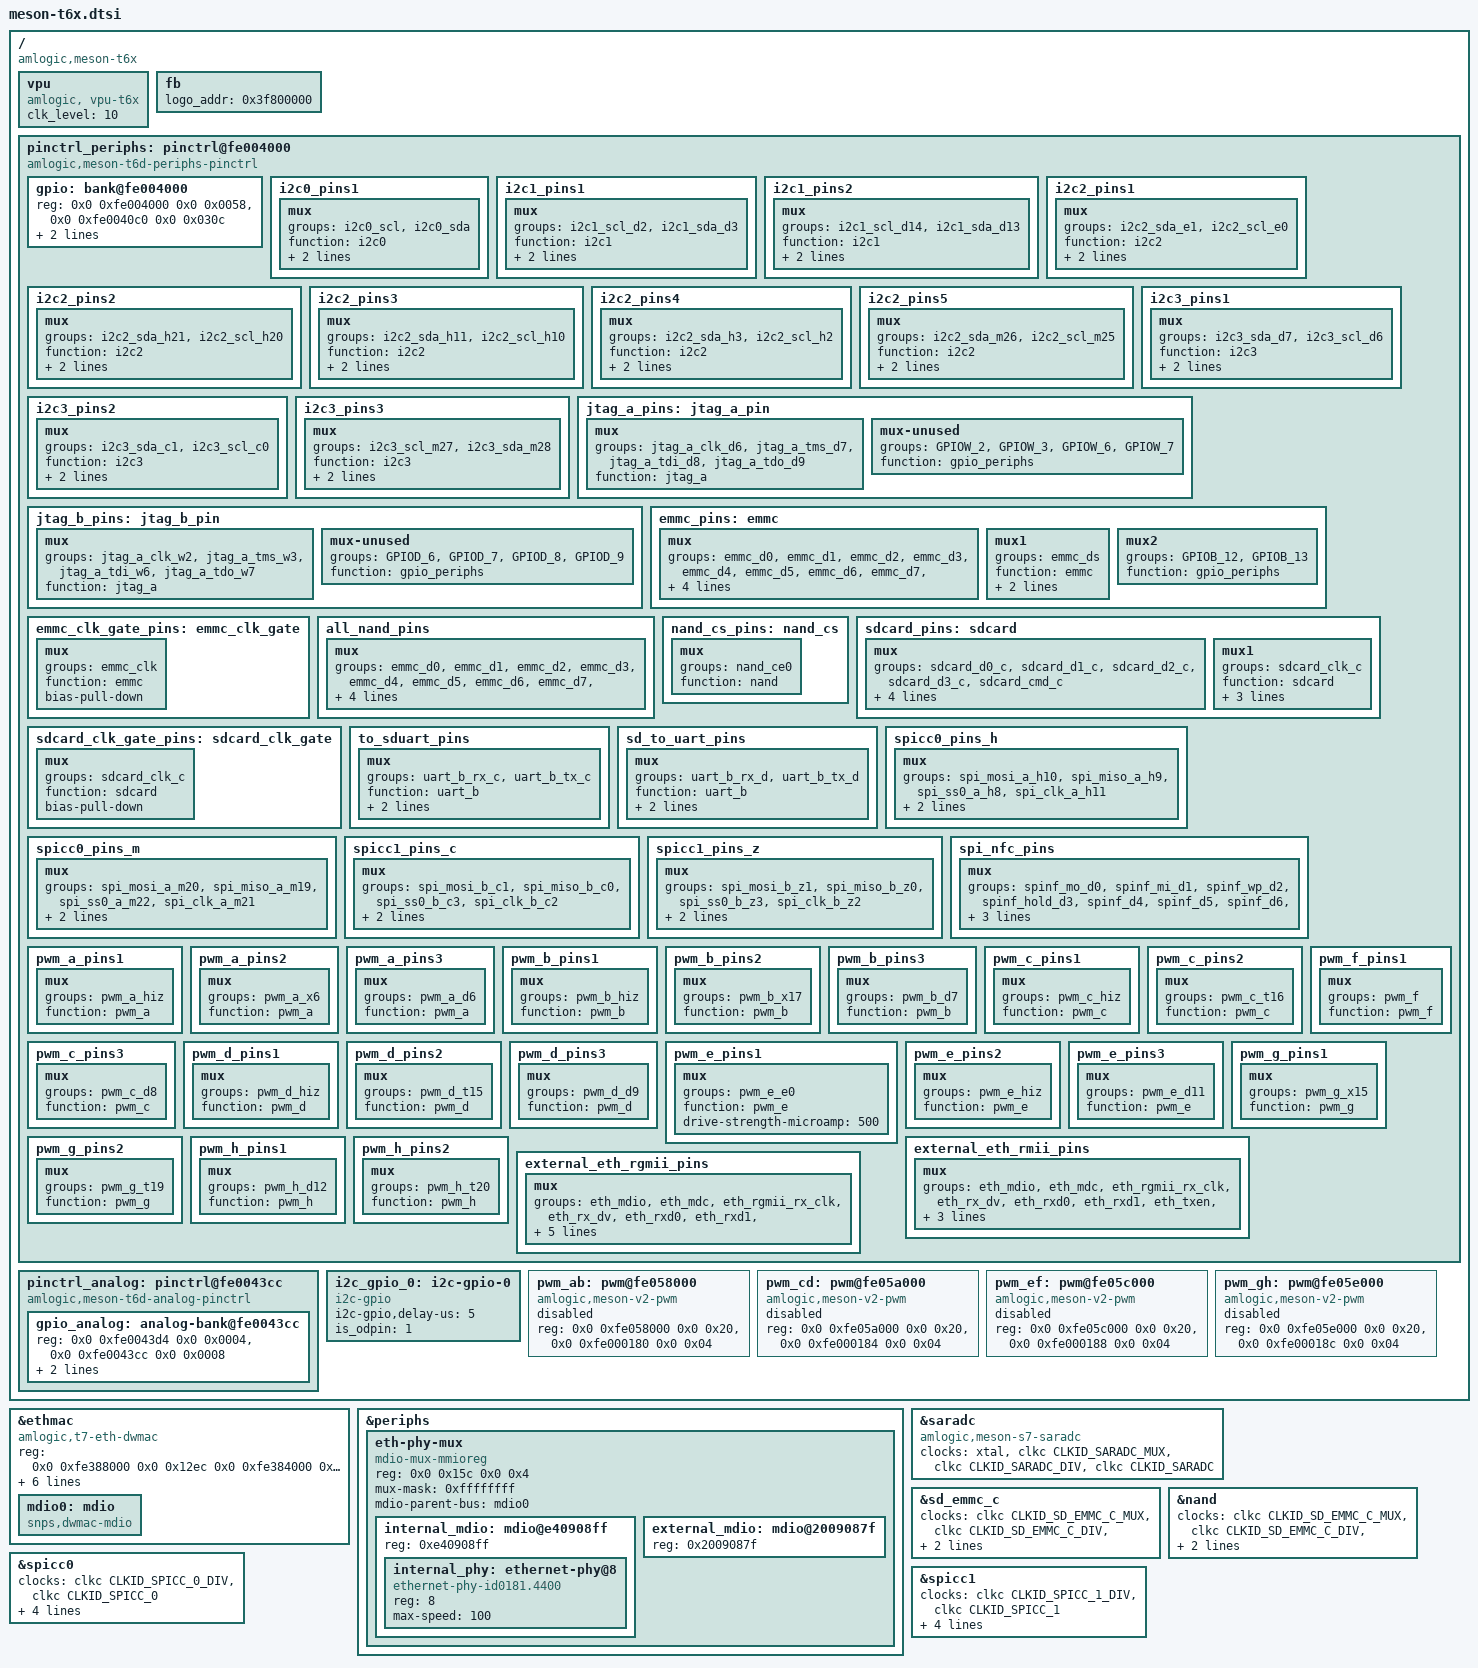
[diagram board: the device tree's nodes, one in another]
// SPDX-License-Identifier: (GPL-2.0+ OR MIT)
/*
 * Copyright (c) 2019 Amlogic, Inc. All rights reserved.
 */

#include "amlogic/meson-t6x-series.dtsi"
#include <dt-bindings/amlogic/gpio/meson-t6x-gpio.h>
#include <dt-bindings/reset/amlogic,meson-gxbb-reset.h>
#include <dt-bindings/amlogic/pwm/pwm.h>
#include <dt-bindings/amlogic/pwm/meson.h>

/ {
	compatible = "amlogic,meson-t6x";

	vpu: vpu {
		compatible = "amlogic, vpu-t6x";
		status = "okay";
		/*clocks = <&clkc CLKID_VAPB_MUX>,
		 *	<&clkc CLKID_VPU_INTR>,
		 *	<&clkc CLKID_VPU_P0_COMP>,
		 *	<&clkc CLKID_VPU_P1_COMP>,
		 *	<&clkc CLKID_VPU_MUX>;
		 *clock-names = "vapb_clk",
		 *	"vpu_intr_gate",
		 *	"vpu_clk0",
		 *	"vpu_clk1",
		 *	"vpu_clk";
		 */
		clk_level = <10>;
		/* 0: 100.0M    1: 166.7M    2: 200.0M    3: 250.0M */
		/* 4: 333.3M    5: 400.0M    6: 500.0M    7: 666.7M */
		/* 8: 800.0M    9: 696.0M(invalid)  10: 840.0M   11: 808.0M   */
	};

	fb {
		status = "okay";
		logo_addr = "0x3f800000";
	};

	pinctrl_periphs: pinctrl@fe004000 {
		compatible = "amlogic,meson-t6d-periphs-pinctrl";
		#address-cells = <2>;
		#size-cells = <2>;
		ranges;

		gpio: bank@fe004000 {
			reg = <0x0 0xfe004000 0x0 0x0058>,
			      <0x0 0xfe0040c0 0x0 0x030c>;
			reg-names = "mux", "gpio";
			gpio-controller;
			#gpio-cells = <2>;
			gpio-ranges = <&pinctrl_periphs 0 0 129>;
		};
	};

	pinctrl_analog: pinctrl@fe0043cc {
		compatible = "amlogic,meson-t6d-analog-pinctrl";
		#address-cells = <2>;
		#size-cells = <2>;
		ranges;

		gpio_analog: analog-bank@fe0043cc {
			reg = <0x0 0xfe0043d4 0x0 0x0004>,
			      <0x0 0xfe0043cc 0x0 0x0008>;
			reg-names = "mux", "gpio";
			gpio-controller;
			#gpio-cells = <2>;
			gpio-ranges = <&pinctrl_analog 0 0 2>;
		};
	};

	i2c_gpio_0: i2c-gpio-0 {
		#address-cells = <1>;
		#size-cells = <0>;

		compatible = "i2c-gpio";
		status = "okay";
		//gpios = <&gpio GPIOH_0 GPIO_ACTIVE_HIGH>, /* SDA */
		//	<&gpio GPIOH_1 GPIO_ACTIVE_HIGH>; /* CLK */

		i2c-gpio,delay-us = <5>;
		is_odpin = <1>;
	};

	pwm_ab: pwm@fe058000 {
		compatible = "amlogic,meson-v2-pwm";
		reg = <0x0 0xfe058000  0x0 0x20>,
			<0x0 0xfe000180  0x0 0x04>;
		#pwm-cells = <3>;
		status = "disabled";
	};

	pwm_cd: pwm@fe05a000 {
		compatible = "amlogic,meson-v2-pwm";
		reg = <0x0 0xfe05a000  0x0 0x20>,
			<0x0 0xfe000184  0x0 0x04>;
		#pwm-cells = <3>;
		status = "disabled";
	};

	pwm_ef: pwm@fe05c000 {
		compatible = "amlogic,meson-v2-pwm";
		reg = <0x0 0xfe05c000  0x0 0x20>,
			<0x0 0xfe000188  0x0 0x04>;
		#pwm-cells = <3>;
		status = "disabled";
	};

	pwm_gh: pwm@fe05e000 {
		compatible = "amlogic,meson-v2-pwm";
		reg = <0x0 0xfe05e000  0x0 0x20>,
			<0x0 0xfe00018c  0x0 0x04>;
			#pwm-cells = <3>;
		status = "disabled";
	};

};

&ethmac {
	compatible = "amlogic,t7-eth-dwmac";
	reg = <0x0 0xfe388000 0x0 0x12ec
		0x0 0xfe384000 0x0 0x8
		0x0 0xfe380000 0x0 0xa0>;
	reg-names = "eth_base", "eth_top", "eth_cfg";
	phy_cntl1 = <0x41054147>;
	internal_phy = <1>;
	mc_val = <0x4be04>;
	pll_val = <0x608200a0 0xea002000 0x00000150>;
	analog_val = <0x20200000 0x0000c000 0x00000023>;
	chip_num = <3>;
//	soc_num = <5>;
	/* 5: S1A, S7 */
	//tx_amp_src = <0xfe005b30>;
//	clocks = <&clkc CLKID_ETH_CORE>,
//		 <&clkc CLKID_FCLK_DIV2>,
//		 <&clkc CLKID_MPLL2>;
//	clock-names = "stmmaceth", "clkin0", "clkin1";

	mdio0: mdio {
		#address-cells = <1>;
		#size-cells = <0>;
		compatible = "snps,dwmac-mdio";
	};
};

&periphs {

	eth-phy-mux {
		compatible = "mdio-mux-mmioreg", "mdio-mux";
		#address-cells = <1>;
		#size-cells = <0>;
		reg = <0x0 0x15c 0x0 0x4>;
		mux-mask = <0xffffffff>;
		mdio-parent-bus = <&mdio0>;

		internal_mdio: mdio@e40908ff {
			reg = <0xe40908ff>;
			#address-cells = <1>;
			#size-cells = <0>;

			internal_phy: ethernet-phy@8 {
				compatible = "ethernet-phy-id0181.4400", "ethernet-phy-ieee802.3-c22";
				reg = <8>;
				max-speed = <100>;
			};
		};

		external_mdio: mdio@2009087f {
			reg = <0x2009087f>;
			#address-cells = <1>;
			#size-cells = <0>;
		};
	};
};

&saradc {
	compatible = "amlogic,meson-s7-saradc", "amlogic,meson-saradc";
	clocks = <&xtal>,
		 <&clkc CLKID_SARADC_MUX>,
		 <&clkc CLKID_SARADC_DIV>,
		 <&clkc CLKID_SARADC>;
	clock-names = "xtal", "adc_mux", "adc_div", "adc_gate";
};

&sd_emmc_c {
	 clocks = <&clkc CLKID_SD_EMMC_C_MUX>,
			<&clkc CLKID_SD_EMMC_C_DIV>,
			<&clkc CLKID_SD_EMMC_C>,
			<&clkc CLKID_GP0_PLL>,
			//<&clkc CLKID_FCLK_DIV2>,
			<&clkc CLKID_XTAL>;
			clock-names = "mux", "div", "gate", "clkin", "xtal";
};

&nand {
	clocks = <&clkc CLKID_SD_EMMC_C_MUX>,
			<&clkc CLKID_SD_EMMC_C_DIV>,
			<&clkc CLKID_SD_EMMC_C>,
			<&clkc CLKID_FCLK_DIV2>,
			<&clkc CLKID_XTAL>;
	clock-names = "mux", "div", "gate", "fdiv2", "xtal";
};

&spicc0 {
	clocks = <&clkc CLKID_SPICC_0_DIV>, <&clkc CLKID_SPICC_0>;
	clock-names = "spi_clk", "sys_clk";
	assigned-clocks = <&clkc CLKID_SPICC_0_MUX>, <&clkc CLKID_SPICC_0_DIV>;
	assigned-clock-parents = <&clkc CLKID_FCLK_DIV2>;
	assigned-clock-rates = <0>, <500000000>;
};

&spicc1 {
	clocks = <&clkc CLKID_SPICC_1_DIV>, <&clkc CLKID_SPICC_1>;
	clock-names = "spi_clk", "sys_clk";
	assigned-clocks = <&clkc CLKID_SPICC_1_MUX>, <&clkc CLKID_SPICC_1_DIV>;
	assigned-clock-parents = <&clkc CLKID_FCLK_DIV2>;
	assigned-clock-rates = <0>, <500000000>;
};

&pinctrl_periphs {
	i2c0_pins1:i2c0_pins1 {
		mux {
			groups = "i2c0_scl",
				"i2c0_sda";
			function = "i2c0";
			drive-strength = <3>;
			bias-disable;
		};
	};

	i2c1_pins1:i2c1_pins1 {
		mux {
			groups = "i2c1_scl_d2",
				"i2c1_sda_d3";
			function = "i2c1";
			drive-strength = <3>;
			bias-disable;
		};
	};

	i2c1_pins2:i2c1_pins2 {
		mux {
			groups = "i2c1_scl_d14",
				"i2c1_sda_d13";
			function = "i2c1";
			drive-strength = <3>;
			bias-disable;
		};
	};

	i2c2_pins1:i2c2_pins1 {
		mux {
			groups = "i2c2_sda_e1",
				"i2c2_scl_e0";
			function = "i2c2";
			drive-strength = <3>;
			bias-disable;
		};
	};

	i2c2_pins2:i2c2_pins2 {
		mux {
			groups = "i2c2_sda_h21",
				"i2c2_scl_h20";
			function = "i2c2";
			drive-strength = <3>;
			bias-disable;
		};
	};

	i2c2_pins3:i2c2_pins3 {
		mux {
			groups = "i2c2_sda_h11",
				"i2c2_scl_h10";
			function = "i2c2";
			drive-strength = <3>;
			bias-disable;
		};
	};

	i2c2_pins4:i2c2_pins4 {
		mux {
			groups = "i2c2_sda_h3",
				"i2c2_scl_h2";
			function = "i2c2";
			drive-strength = <3>;
			bias-disable;
		};
	};

	i2c2_pins5:i2c2_pins5 {
		mux {
			groups = "i2c2_sda_m26",
				"i2c2_scl_m25";
			function = "i2c2";
			drive-strength = <3>;
			bias-disable;
		};
	};

	i2c3_pins1:i2c3_pins1 {
		mux {
			groups = "i2c3_sda_d7",
				"i2c3_scl_d6";
			function = "i2c3";
			drive-strength = <3>;
			bias-disable;
		};
	};

	i2c3_pins2:i2c3_pins2 {
		mux {
			groups = "i2c3_sda_c1",
				"i2c3_scl_c0";
			function = "i2c3";
			drive-strength = <3>;
			bias-disable;
		};
	};

	i2c3_pins3:i2c3_pins3 {
		mux {
			groups = "i2c3_scl_m27",
				"i2c3_sda_m28";
			function = "i2c3";
			drive-strength = <3>;
			bias-disable;
		};
	};

	jtag_a_pins: jtag_a_pin {
		mux {
			groups = "jtag_a_clk_d6",
				 "jtag_a_tms_d7",
				 "jtag_a_tdi_d8",
				 "jtag_a_tdo_d9";
			function = "jtag_a";
		};

		mux-unused {
			groups = "GPIOW_2",
				 "GPIOW_3",
				 "GPIOW_6",
				 "GPIOW_7";
			function = "gpio_periphs";
		};
	};

	jtag_b_pins: jtag_b_pin {
		mux {
			groups = "jtag_a_clk_w2",
				 "jtag_a_tms_w3",
				 "jtag_a_tdi_w6",
				 "jtag_a_tdo_w7";
			function = "jtag_a";
		};

		mux-unused {
			groups = "GPIOD_6",
				 "GPIOD_7",
				 "GPIOD_8",
				 "GPIOD_9";
			function = "gpio_periphs";
		};
	};

	emmc_pins: emmc {
		mux {
			groups = "emmc_d0",
				"emmc_d1",
				"emmc_d2",
				"emmc_d3",
				"emmc_d4",
				"emmc_d5",
				"emmc_d6",
				"emmc_d7",
				"emmc_clk",
				"emmc_cmd";
			function = "emmc";
			bias-pull-up;
			input-enable;
		};
		mux1 {
			groups = "emmc_ds";
			function = "emmc";
			input-enable;
			bias-pull-down;
		};
		mux2 {
			groups = "GPIOB_12",
				"GPIOB_13";
			function = "gpio_periphs";
		};
	};

	emmc_clk_gate_pins: emmc_clk_gate {
		mux {
			groups = "emmc_clk";
			function = "emmc";
			bias-pull-down;
		};
	};

	all_nand_pins: all_nand_pins {
		mux {
			groups =  "emmc_d0",
				"emmc_d1",
				"emmc_d2",
				"emmc_d3",
				"emmc_d4",
				"emmc_d5",
				"emmc_d6",
				"emmc_d7",
				"nand_ce0",
				"nand_ale",
				"nand_cle",
				"nand_wen_clk",
				"nand_ren_wr";
			function = "nand";
			input-enable;
		};
	};

	nand_cs_pins: nand_cs {
		mux {
			groups = "nand_ce0";
			function = "nand";
		};
	};

	sdcard_pins: sdcard {
		mux {
			groups = "sdcard_d0_c",
				"sdcard_d1_c",
				"sdcard_d2_c",
				"sdcard_d3_c",
				"sdcard_cmd_c";
			function = "sdcard";
			bias-pull-up;
			input-enable;
			drive-strength = <4>;
		};
		mux1 {
			groups ="sdcard_clk_c";
			function = "sdcard";
			bias-pull-up;
			output-high;
			drive-strength = <4>;
		};
	};

	sdcard_clk_gate_pins: sdcard_clk_gate {
		mux {
			groups = "sdcard_clk_c";
			function = "sdcard";
			bias-pull-down;
		};
	};

	to_sduart_pins: to_sduart_pins{
		mux {
			groups = "uart_b_rx_c", "uart_b_tx_c";
			function = "uart_b";
			bias-pull-up;
			input-enable;
		};
	};

	sd_to_uart_pins: sd_to_uart_pins{
		mux {
			groups = "uart_b_rx_d", "uart_b_tx_d";
			function = "uart_b";
			bias-pull-up;
			input-enable;
		};
	};

	spicc0_pins_h: spicc0_pins_h {
		mux {
			groups = "spi_mosi_a_h10",
				 "spi_miso_a_h9",
				 "spi_ss0_a_h8",
				 "spi_clk_a_h11";
			function = "spi";
			drive-strength-microamp = <3000>;
		};
	};

	spicc0_pins_m: spicc0_pins_m {
		mux {
			groups = "spi_mosi_a_m20",
				 "spi_miso_a_m19",
				 "spi_ss0_a_m22",
				 "spi_clk_a_m21";
			function = "spi";
			drive-strength-microamp = <30000>;
		};
	};

	spicc1_pins_c: spicc1_pins_c {
		mux {
			groups = "spi_mosi_b_c1",
				 "spi_miso_b_c0",
				 "spi_ss0_b_c3",
				 "spi_clk_b_c2";
			function = "spi";
			drive-strength-microamp = <30000>;
		};
	};

	spicc1_pins_z: spicc1_pins_z {
		mux {
			groups = "spi_mosi_b_z1",
				 "spi_miso_b_z0",
				 "spi_ss0_b_z3",
				 "spi_clk_b_z2";
			function = "spi";
			drive-strength-microamp = <30000>;
		};
	};

	spi_nfc_pins: spi_nfc_pins {
		mux {
			groups = "spinf_mo_d0",
				 "spinf_mi_d1",
				 "spinf_wp_d2",
				 "spinf_hold_d3",
				 "spinf_d4",
				 "spinf_d5",
				 "spinf_d6",
				 "spinf_d7",
				 "spinf_clk",
				 "spinf_cs0";
			function = "spinf";
			drive-strength = <3>;
		};
	};

	pwm_a_pins1: pwm_a_pins1 {
		mux {
			groups = "pwm_a_hiz";
			function = "pwm_a";
		};
	};

	pwm_a_pins2: pwm_a_pins2 {
		mux {
			groups = "pwm_a_x6";
			function = "pwm_a";
		};
	};

	pwm_a_pins3: pwm_a_pins3 {
		mux {
			groups = "pwm_a_d6";
			function = "pwm_a";
		};
	};

	pwm_b_pins1: pwm_b_pins1 {
		mux {
			groups = "pwm_b_hiz";
			function = "pwm_b";
		};
	};

	pwm_b_pins2: pwm_b_pins2 {
		mux {
			groups = "pwm_b_x17";
			function = "pwm_b";
		};
	};

	pwm_b_pins3: pwm_b_pins3 {
		mux {
			groups = "pwm_b_d7";
			function = "pwm_b";
		};
	};

	pwm_c_pins1: pwm_c_pins1 {
		mux {
			groups = "pwm_c_hiz";
			function = "pwm_c";
		};
	};

	pwm_c_pins2: pwm_c_pins2 {
		mux {
			groups = "pwm_c_t16";
			function = "pwm_c";
		};
	};

	pwm_c_pins3: pwm_c_pins3 {
		mux {
			groups = "pwm_c_d8";
			function = "pwm_c";
		};
	};

	pwm_d_pins1: pwm_d_pins1 {
		mux {
			groups = "pwm_d_hiz";
			function = "pwm_d";
		};
	};

	pwm_d_pins2: pwm_d_pins2 {
		mux {
			groups = "pwm_d_t15";
			function = "pwm_d";
		};
	};

	pwm_d_pins3: pwm_d_pins3 {
		mux {
			groups = "pwm_d_d9";
			function = "pwm_d";
		};
	};

	pwm_e_pins1: pwm_e_pins1 {
		mux {
			groups = "pwm_e_e0";
			function = "pwm_e";
			drive-strength-microamp = <500>;
		};
	};

	pwm_e_pins2: pwm_e_pins2 {
		mux {
			groups = "pwm_e_hiz";
			function = "pwm_e";
		};
	};

	pwm_e_pins3: pwm_e_pins3 {
		mux {
			groups = "pwm_e_d11";
			function = "pwm_e";
		};
	};

	pwm_f_pins1: pwm_f_pins1 {
		mux {
			groups = "pwm_f";
			function = "pwm_f";
		};
	};

	pwm_g_pins1: pwm_g_pins1 {
		mux {
			groups = "pwm_g_x15";
			function = "pwm_g";
		};
	};

	pwm_g_pins2: pwm_g_pins2 {
		mux {
			groups = "pwm_g_t19";
			function = "pwm_g";
		};
	};

	pwm_h_pins1: pwm_h_pins1 {
		mux {
			groups = "pwm_h_d12";
			function = "pwm_h";
		};
	};

	pwm_h_pins2: pwm_h_pins2 {
		mux {
			groups = "pwm_h_t20";
			function = "pwm_h";
		};
	};

	external_eth_rmii_pins: external_eth_rmii_pins {
		mux {
			groups = "eth_mdio",
				"eth_mdc",
				"eth_rgmii_rx_clk",
				"eth_rx_dv",
				"eth_rxd0",
				"eth_rxd1",
				"eth_txen",
				"eth_txd0",
				"eth_txd1";
			function = "eth";
			drive-strength = <3>;
		};
	};

	external_eth_rgmii_pins: external_eth_rgmii_pins {
		mux {
			groups = "eth_mdio",
				"eth_mdc",
				"eth_rgmii_rx_clk",
				"eth_rx_dv",
				"eth_rxd0",
				"eth_rxd1",
				"eth_rxd2_rgmii",
				"eth_rxd3_rgmii",
				"eth_rgmii_tx_clk",
				"eth_txen",
				"eth_txd0",
				"eth_txd1",
				"eth_txd2_rgmii",
				"eth_txd3_rgmii";
			function = "eth";
			drive-strength = <3>;
		};
	};
};
